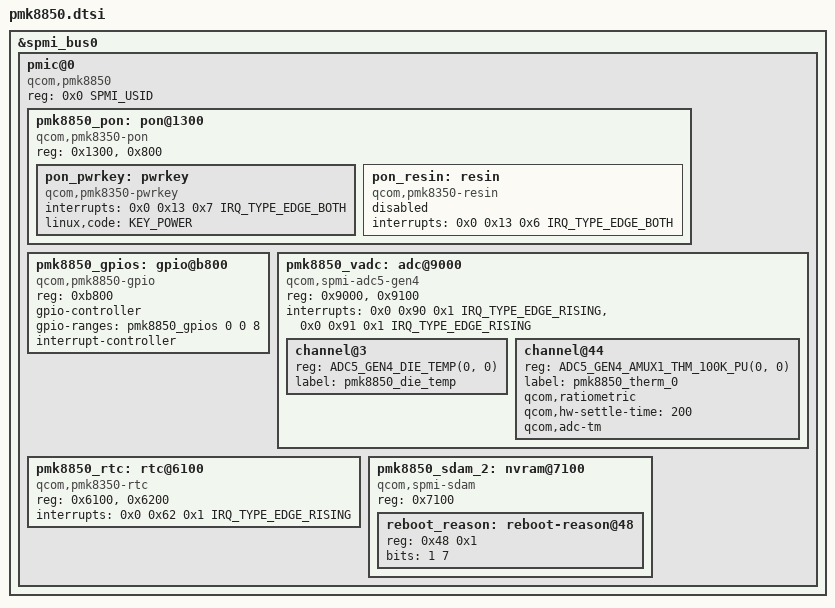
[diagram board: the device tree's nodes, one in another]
// SPDX-License-Identifier: BSD-3-Clause
/*
 * Copyright (c) Qualcomm Technologies, Inc. and/or its subsidiaries.
 */

#include <dt-bindings/input/input.h>
#include <dt-bindings/input/linux-event-codes.h>
#include <dt-bindings/interrupt-controller/irq.h>
#include <dt-bindings/spmi/spmi.h>
#include "qcom-adc5-gen4.h"

&spmi_bus0 {
	pmic@0 {
		compatible = "qcom,pmk8850", "qcom,spmi-pmic";
		reg = <0x0 SPMI_USID>;
		#address-cells = <1>;
		#size-cells = <0>;

		pmk8850_pon: pon@1300 {
			compatible = "qcom,pmk8350-pon";
			reg = <0x1300>,
			      <0x800>;
			reg-names = "hlos",
				    "pbs";

			pon_pwrkey: pwrkey {
				compatible = "qcom,pmk8350-pwrkey";
				interrupts = <0x0 0x13 0x7 IRQ_TYPE_EDGE_BOTH>;
				linux,code = <KEY_POWER>;
			};

			pon_resin: resin {
				compatible = "qcom,pmk8350-resin";
				interrupts = <0x0 0x13 0x6 IRQ_TYPE_EDGE_BOTH>;
				status = "disabled";
			};
		};

		pmk8850_gpios: gpio@b800 {
			compatible = "qcom,pmk8850-gpio", "qcom,spmi-gpio";
			reg = <0xb800>;
			gpio-controller;
			gpio-ranges = <&pmk8850_gpios 0 0 8>;
			#gpio-cells = <2>;
			interrupt-controller;
			#interrupt-cells = <2>;
		};

		pmk8850_vadc: adc@9000 {
			compatible = "qcom,spmi-adc5-gen4";
			reg = <0x9000>, <0x9100>;
			#address-cells = <1>;
			#size-cells = <0>;
			interrupts = <0x0 0x90 0x1 IRQ_TYPE_EDGE_RISING>,
				     <0x0 0x91 0x1 IRQ_TYPE_EDGE_RISING>;
			#thermal-sensor-cells = <1>;
			#io-channel-cells = <1>;

			channel@3 {
				reg = <ADC5_GEN4_DIE_TEMP(0, 0)>;
				label = "pmk8850_die_temp";
			};

			channel@44 {
				reg = <ADC5_GEN4_AMUX1_THM_100K_PU(0, 0)>;
				label = "pmk8850_therm_0";
				qcom,ratiometric;
				qcom,hw-settle-time = <200>;
				qcom,adc-tm;
			};
		};

		pmk8850_rtc: rtc@6100 {
			compatible = "qcom,pmk8350-rtc";
			reg = <0x6100>,
			      <0x6200>;
			reg-names = "rtc",
				    "alarm";
			interrupts = <0x0 0x62 0x1 IRQ_TYPE_EDGE_RISING>;
		};

		pmk8850_sdam_2: nvram@7100 {
			compatible = "qcom,spmi-sdam";
			reg = <0x7100>;
			#address-cells = <1>;
			#size-cells = <1>;
			ranges = <0 0x7100 0x100>;

			reboot_reason: reboot-reason@48 {
				reg = <0x48 0x1>;
				bits = <1 7>;
			};
		};
	};
};
